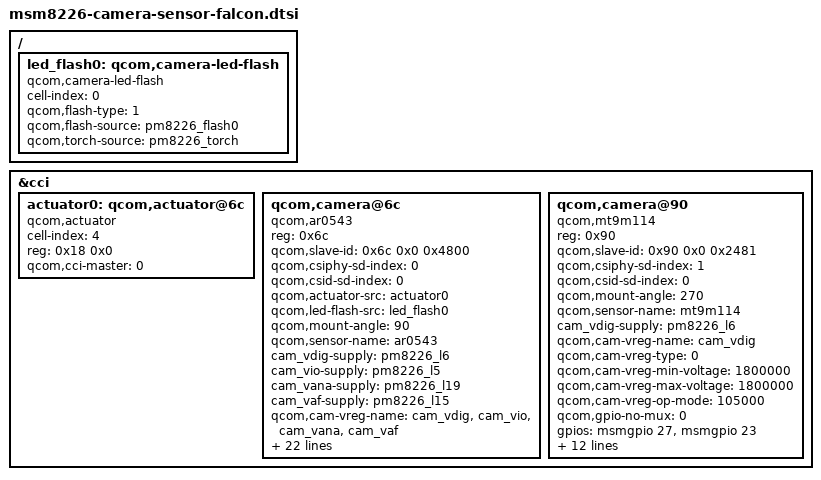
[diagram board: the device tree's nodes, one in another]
/*
 * Copyright (c) 2013, The Linux Foundation. All rights reserved.
 *
 * This program is free software; you can redistribute it and/or modify
 * it under the terms of the GNU General Public License version 2 and
 * only version 2 as published by the Free Software Foundation.
 *
 * This program is distributed in the hope that it will be useful,
 * but WITHOUT ANY WARRANTY; without even the implied warranty of
 * MERCHANTABILITY or FITNESS FOR A PARTICULAR PURPOSE.  See the
 * GNU General Public License for more details.
 */

/ {

	led_flash0: qcom,camera-led-flash {
		cell-index = <0>;
		compatible = "qcom,camera-led-flash";
		qcom,flash-type = <1>;
		qcom,flash-source = <&pm8226_flash0>;
		qcom,torch-source = <&pm8226_torch>;
	};
};

&cci {
	actuator0: qcom,actuator@6c {
		cell-index = <4>;
		reg = <0x18 0x0>;
		compatible = "qcom,actuator";
		qcom,cci-master = <0>;
	};

	qcom,camera@6c {
		compatible = "qcom,ar0543";
		reg = <0x6c>;
		qcom,slave-id = <0x6c 0x0 0x4800>;
		qcom,csiphy-sd-index = <0>;
		qcom,csid-sd-index = <0>;
		qcom,actuator-src = <&actuator0>;
		qcom,led-flash-src = <&led_flash0>;
		qcom,mount-angle = <90>;
		qcom,sensor-name = "ar0543";
		cam_vdig-supply = <&pm8226_l6>;
		cam_vio-supply = <&pm8226_l5>;
		cam_vana-supply = <&pm8226_l19>;
		cam_vaf-supply = <&pm8226_l15>;
		qcom,cam-vreg-name = "cam_vdig", "cam_vio", "cam_vana", "cam_vaf";
		qcom,cam-vreg-type = <0 1 1 0>;
		qcom,cam-vreg-min-voltage = <1800000 0 0 2800000>;
		qcom,cam-vreg-max-voltage = <1800000 0 0 2800000>;
		qcom,cam-vreg-op-mode = <105000 0 0 100000>;
		qcom,gpio-no-mux = <0>;
		gpios = <&msmgpio 26 0>,
			<&msmgpio 37 0>,
			<&msmgpio 36 0>,
			<&msmgpio 23 0>;
		qcom,gpio-reset = <1>;
		qcom,gpio-standby = <2>;
		qcom,gpio-pwren = <3>;
		qcom,gpio-req-tbl-num = <0 1 2 3>;
		qcom,gpio-req-tbl-flags = <1 0 0 0>;
		qcom,gpio-req-tbl-label = "CAMIF_MCLK",
					  "CAM_RESET1",
					  "CAM_STANDBY",
					  "CAM_PWREN";
		qcom,gpio-set-tbl-num = <1 1>;
		qcom,gpio-set-tbl-flags = <0 2>;
		qcom,gpio-set-tbl-delay = <1000 30000>;
		qcom,csi-lane-assign = <0x4320>;
		qcom,csi-lane-mask = <0x7>;
		qcom,sensor-position = <0>;
		qcom,sensor-mode = <1>;
		qcom,cci-master = <0>;
		status = "ok";
	};

	qcom,camera@90 {
		compatible = "qcom,mt9m114";
		reg = <0x90>;
		qcom,slave-id = <0x90 0x0 0x2481>;
		qcom,csiphy-sd-index = <1>;
		qcom,csid-sd-index = <0>;
		qcom,mount-angle = <270>;
		qcom,sensor-name = "mt9m114";
		cam_vdig-supply = <&pm8226_l6>;
		qcom,cam-vreg-name = "cam_vdig";
		qcom,cam-vreg-type = <0>;
		qcom,cam-vreg-min-voltage = <1800000>;
		qcom,cam-vreg-max-voltage = <1800000>;
		qcom,cam-vreg-op-mode = <105000>;
		qcom,gpio-no-mux = <0>;
		gpios = <&msmgpio 27 0>,
			<&msmgpio 23 0>;
		qcom,gpio-pwren = <1>;
		qcom,gpio-req-tbl-num = <0 1>;
		qcom,gpio-req-tbl-flags = <1 0>;
		qcom,gpio-req-tbl-label = "CAMIF_MCLK",
					  "CAM_PWREN";
		qcom,gpio-set-tbl-num = <1 1>;
		qcom,gpio-set-tbl-flags = <0 2>;
		qcom,gpio-set-tbl-delay = <1000 4000>;
		qcom,csi-lane-assign = <0x4320>;
		qcom,csi-lane-mask = <0x3>;
		qcom,sensor-position = <1>;
		qcom,sensor-mode = <1>;
		qcom,cci-master = <0>;
		status = "ok";
	};
};
